VERSION ""

NS_ :

BS_:

BU_:

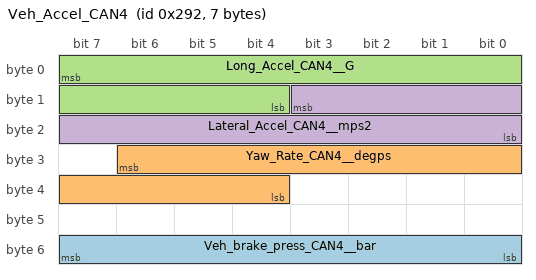
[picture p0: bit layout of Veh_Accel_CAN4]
BO_ 658 Veh_Accel_CAN4: 7 Vector__XXX
 SG_ Veh_brake_press_CAN4__bar : 55|8@0+ (1,0) [0|255] "" Vector__XXX
 SG_ Yaw_Rate_CAN4__degps : 30|11@0- (0.1,0) [-102.4|102.3] "deg/s" Vector__XXX
 SG_ Long_Accel_CAN4__G : 7|12@0+ (0.001,-2) [-2|2.095] "G" Vector__XXX
 SG_ Lateral_Accel_CAN4__mps2 : 11|12@0+ (0.01,-20) [-20|20.95] "m/s^2" Vector__XXX

BO_ 569 Pedal_Accel_CAN4: 6 Vector__XXX
 SG_ pedal_accel_pos_CAN4__per : 47|8@0+ (0.5,0) [0|127.5] "%" Vector__XXX

BO_ 853 Veh_Speed: 4 Vector__XXX
 SG_ veh_speed_CAN4__kph : 23|16@0+ (0.01,0) [0|655.35] "kph" Vector__XXX

BO_ 645 Veh_Speed1: 4 Vector__XXX
 SG_ veh_speed1_CAN4__kph : 23|16@0+ (0.005,0) [0|327.675] "kph" Vector__XXX

BO_ 389 Steering: 2 Vector__XXX
 SG_ steering_torque_sens_CAN4__Nm : 6|11@0- (0.01,0) [-10.24|10.23] "Nm" Vector__XXX

BO_ 403 Steering1: 2 Vector__XXX
 SG_ steering_motor_current_CAN4__A : 6|12@0- (0.0414,4.325) [-80.4622|89.07080000000001] "A" Vector__XXX
